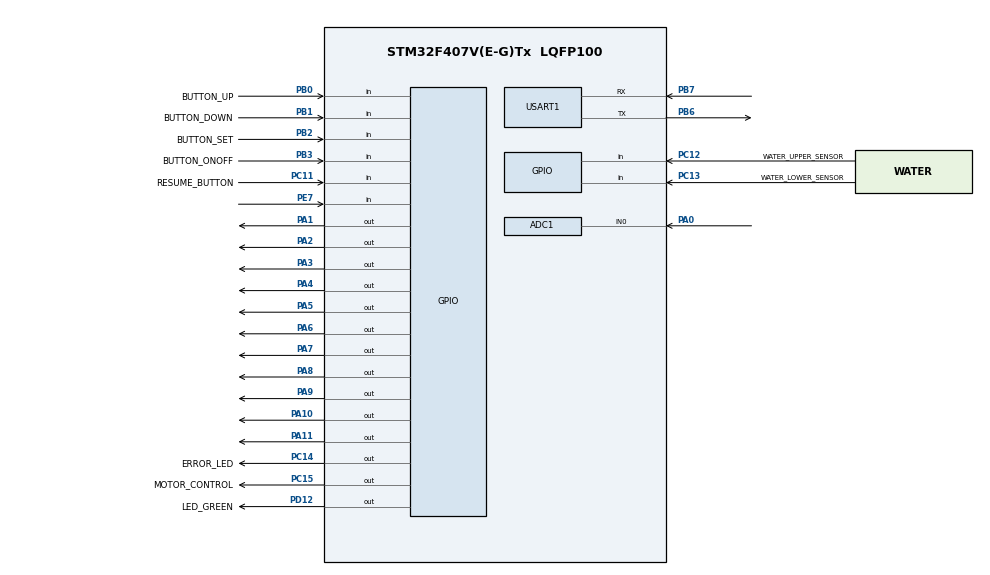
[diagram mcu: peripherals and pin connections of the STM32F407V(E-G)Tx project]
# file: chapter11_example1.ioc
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ADC1.Channel-0\#ChannelRegularConversion=ADC_CHANNEL_0
ADC1.NbrOfConversionFlag=1
ADC1.Rank-0\#ChannelRegularConversion=1
ADC1.SamplingTime-0\#ChannelRegularConversion=ADC_SAMPLETIME_15CYCLES
ADC1.master=1
Mcu.Family=STM32F4
Mcu.Name=STM32F407V(E-G)Tx
Mcu.Package=LQFP100
NVIC.PriorityGroup=NVIC_PRIORITYGROUP_4
PA0-WKUP.Signal=SharedAnalog_PA0
PA1.Signal=GPIO_Output
PA10.Signal=GPIO_Output
PA11.Signal=GPIO_Output
PA2.Signal=GPIO_Output
PA3.Signal=GPIO_Output
PA4.Signal=GPIO_Output
PA5.Signal=GPIO_Output
PA6.Signal=GPIO_Output
PA7.Signal=GPIO_Output
PA8.Signal=GPIO_Output
PA9.Signal=GPIO_Output
PB0.GPIO_Label=BUTTON_UP
PB0.GPIO_PuPd=GPIO_PULLUP
PB0.Signal=GPIO_Input
PB1.GPIO_Label=BUTTON_DOWN
PB1.GPIO_PuPd=GPIO_PULLUP
PB1.Signal=GPIO_Input
PB2.GPIO_Label=BUTTON_SET
PB2.GPIO_PuPd=GPIO_PULLUP
PB2.Signal=GPIO_Input
PB3.GPIO_Label=BUTTON_ONOFF
PB3.GPIO_PuPd=GPIO_PULLUP
PB3.Signal=GPIO_Input
PB6.Mode=Asynchronous
PB6.Signal=USART1_TX
PB7.Mode=Asynchronous
PB7.Signal=USART1_RX
PC11.GPIO_Label=RESUME_BUTTON
PC11.GPIO_PuPd=GPIO_PULLUP
PC11.Signal=GPIO_Input
PC12.GPIO_Label=WATER_UPPER_SENSOR
PC12.GPIO_PuPd=GPIO_PULLUP
PC12.Signal=GPIO_Input
PC13-ANTI_TAMP.GPIO_Label=WATER_LOWER_SENSOR
PC13-ANTI_TAMP.GPIO_PuPd=GPIO_PULLUP
PC13-ANTI_TAMP.Signal=GPIO_Input
PC14-OSC32_IN.GPIO_Label=ERROR_LED
PC14-OSC32_IN.Signal=GPIO_Output
PC15-OSC32_OUT.GPIO_Label=MOTOR_CONTROL
PC15-OSC32_OUT.Signal=GPIO_Output
PD12.GPIO_Label=LED_GREEN
PD12.Signal=GPIO_Output
PE7.Signal=GPIO_Input
ProjectManager.HeapSize=0x200
ProjectManager.StackSize=0x400
ProjectManager.TargetToolchain=STM32CubeIDE
RCC.AHBFreq_Value=16000000
RCC.APB1Freq_Value=16000000
RCC.APB2Freq_Value=16000000
RCC.CortexFreq_Value=16000000
RCC.HSE_VALUE=25000000
RCC.HSI_VALUE=16000000
RCC.LSE_VALUE=32768
RCC.SYSCLKFreq_VALUE=16000000
RCC.VCOOutputFreq_Value=192000000
SH.SharedAnalog_PA0.0=GPIO_Analog
SH.SharedAnalog_PA0.1=ADC1_IN0,IN0
USART1.VirtualMode=VM_ASYNC
board=custom

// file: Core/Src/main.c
/* USER CODE BEGIN Header */
/**
  ******************************************************************************
  * @file           : main.c
  * @brief          : Main program body
  ******************************************************************************
  * @attention
  *
  * Copyright (c) 2025 STMicroelectronics.
  * All rights reserved.
  *
  * This software is licensed under terms that can be found in the LICENSE file
  * in the root directory of this software component.
  * If no LICENSE file comes with this software, it is provided AS-IS.
  *
  ******************************************************************************
  */
/* USER CODE END Header */
#include "main.h"

/* USER CODE BEGIN Includes */
#include "app_main.h"
/* USER CODE END Includes */

void SystemClock_Config(void);
static void MX_GPIO_Init(void);
static void MX_USART1_UART_Init(void);
static void MX_ADC1_Init(void);

int main(void)
{

  /* MCU Configuration--------------------------------------------------------*/

  /* Reset of all peripherals, Initializes the Flash interface and the Systick. */
  LL_APB2_GRP1_EnableClock(LL_APB2_GRP1_PERIPH_SYSCFG);
  LL_APB1_GRP1_EnableClock(LL_APB1_GRP1_PERIPH_PWR);

  /* System interrupt init*/
  NVIC_SetPriorityGrouping(NVIC_PRIORITYGROUP_4);

  /* SysTick_IRQn interrupt configuration */
  NVIC_SetPriority(SysTick_IRQn, NVIC_EncodePriority(NVIC_GetPriorityGrouping(),15, 0));

  /* Configure the system clock */
  SystemClock_Config();

  /* Initialize all configured peripherals */
  MX_GPIO_Init();
  MX_USART1_UART_Init();
  MX_ADC1_Init();

  /* Infinite loop */
  /* USER CODE BEGIN WHILE */
app_main();
  while (1)
  {
    /* USER CODE END WHILE */

  }
}

void SystemClock_Config(void)
{
  LL_FLASH_SetLatency(LL_FLASH_LATENCY_0);
  while(LL_FLASH_GetLatency()!= LL_FLASH_LATENCY_0)
  {
  }
  LL_PWR_SetRegulVoltageScaling(LL_PWR_REGU_VOLTAGE_SCALE1);
  LL_RCC_HSI_SetCalibTrimming(16);
  LL_RCC_HSI_Enable();

   /* Wait till HSI is ready */
  while(LL_RCC_HSI_IsReady() != 1)
  {

  }
  LL_RCC_SetAHBPrescaler(LL_RCC_SYSCLK_DIV_1);
  LL_RCC_SetAPB1Prescaler(LL_RCC_APB1_DIV_1);
  LL_RCC_SetAPB2Prescaler(LL_RCC_APB2_DIV_1);
  LL_RCC_SetSysClkSource(LL_RCC_SYS_CLKSOURCE_HSI);

   /* Wait till System clock is ready */
  while(LL_RCC_GetSysClkSource() != LL_RCC_SYS_CLKSOURCE_STATUS_HSI)
  {

  }
  LL_Init1msTick(16000000);
  LL_SetSystemCoreClock(16000000);
}

static void MX_ADC1_Init(void)
{

  LL_ADC_InitTypeDef ADC_InitStruct = {0};
  LL_ADC_REG_InitTypeDef ADC_REG_InitStruct = {0};
  LL_ADC_CommonInitTypeDef ADC_CommonInitStruct = {0};

  LL_GPIO_InitTypeDef GPIO_InitStruct = {0};

  /* Peripheral clock enable */
  LL_APB2_GRP1_EnableClock(LL_APB2_GRP1_PERIPH_ADC1);

  LL_AHB1_GRP1_EnableClock(LL_AHB1_GRP1_PERIPH_GPIOA);
  /**ADC1 GPIO Configuration
  PA0-WKUP   ------> ADC1_IN0
  */
  GPIO_InitStruct.Pin = LL_GPIO_PIN_0;
  GPIO_InitStruct.Mode = LL_GPIO_MODE_ANALOG;
  GPIO_InitStruct.Pull = LL_GPIO_PULL_NO;
  LL_GPIO_Init(GPIOA, &GPIO_InitStruct);

  /* USER CODE BEGIN ADC1_Init 1 */
  /* Kích hoạt ADC */
   LL_ADC_Enable(ADC1);
   while (!LL_ADC_IsEnabled(ADC1));

   /* Hiệu chuẩn ADC (tùy chọn, nhưng nên có) */

  /* USER CODE END ADC1_Init 1 */

  /** Common config
  */
  ADC_InitStruct.Resolution = LL_ADC_RESOLUTION_12B;
  ADC_InitStruct.DataAlignment = LL_ADC_DATA_ALIGN_RIGHT;
  ADC_InitStruct.SequencersScanMode = LL_ADC_SEQ_SCAN_DISABLE;
  LL_ADC_Init(ADC1, &ADC_InitStruct);
  ADC_REG_InitStruct.TriggerSource = LL_ADC_REG_TRIG_SOFTWARE;
  ADC_REG_InitStruct.SequencerLength = LL_ADC_REG_SEQ_SCAN_DISABLE;
  ADC_REG_InitStruct.SequencerDiscont = LL_ADC_REG_SEQ_DISCONT_DISABLE;
  ADC_REG_InitStruct.ContinuousMode = LL_ADC_REG_CONV_SINGLE;
  ADC_REG_InitStruct.DMATransfer = LL_ADC_REG_DMA_TRANSFER_NONE;
  LL_ADC_REG_Init(ADC1, &ADC_REG_InitStruct);
  LL_ADC_REG_SetFlagEndOfConversion(ADC1, LL_ADC_REG_FLAG_EOC_UNITARY_CONV);
  ADC_CommonInitStruct.CommonClock = LL_ADC_CLOCK_SYNC_PCLK_DIV2;
  ADC_CommonInitStruct.Multimode = LL_ADC_MULTI_INDEPENDENT;
  LL_ADC_CommonInit(__LL_ADC_COMMON_INSTANCE(ADC1), &ADC_CommonInitStruct);

  /** Configure Regular Channel
  */
  LL_ADC_REG_SetSequencerRanks(ADC1, LL_ADC_REG_RANK_1, LL_ADC_CHANNEL_0);
  LL_ADC_SetChannelSamplingTime(ADC1, LL_ADC_CHANNEL_0, LL_ADC_SAMPLINGTIME_15CYCLES);

}

static void MX_USART1_UART_Init(void)
{

  LL_USART_InitTypeDef USART_InitStruct = {0};

  LL_GPIO_InitTypeDef GPIO_InitStruct = {0};

  /* Peripheral clock enable */
  LL_APB2_GRP1_EnableClock(LL_APB2_GRP1_PERIPH_USART1);

  LL_AHB1_GRP1_EnableClock(LL_AHB1_GRP1_PERIPH_GPIOB);
  /**USART1 GPIO Configuration
  PB6   ------> USART1_TX
  PB7   ------> USART1_RX
  */
  GPIO_InitStruct.Pin = LL_GPIO_PIN_6|LL_GPIO_PIN_7;
  GPIO_InitStruct.Mode = LL_GPIO_MODE_ALTERNATE;
  GPIO_InitStruct.Speed = LL_GPIO_SPEED_FREQ_VERY_HIGH;
  GPIO_InitStruct.OutputType = LL_GPIO_OUTPUT_PUSHPULL;
  GPIO_InitStruct.Pull = LL_GPIO_PULL_NO;
  GPIO_InitStruct.Alternate = LL_GPIO_AF_7;
  LL_GPIO_Init(GPIOB, &GPIO_InitStruct);

  USART_InitStruct.BaudRate = 115200;
  USART_InitStruct.DataWidth = LL_USART_DATAWIDTH_8B;
  USART_InitStruct.StopBits = LL_USART_STOPBITS_1;
  USART_InitStruct.Parity = LL_USART_PARITY_NONE;
  USART_InitStruct.TransferDirection = LL_USART_DIRECTION_TX_RX;
  USART_InitStruct.HardwareFlowControl = LL_USART_HWCONTROL_NONE;
  USART_InitStruct.OverSampling = LL_USART_OVERSAMPLING_16;
  LL_USART_Init(USART1, &USART_InitStruct);
  LL_USART_ConfigAsyncMode(USART1);
  LL_USART_Enable(USART1);

}

static void MX_GPIO_Init(void)
{
  LL_GPIO_InitTypeDef GPIO_InitStruct = {0};

  /* GPIO Ports Clock Enable */
  LL_AHB1_GRP1_EnableClock(LL_AHB1_GRP1_PERIPH_GPIOC);
  LL_AHB1_GRP1_EnableClock(LL_AHB1_GRP1_PERIPH_GPIOA);
  LL_AHB1_GRP1_EnableClock(LL_AHB1_GRP1_PERIPH_GPIOB);
  LL_AHB1_GRP1_EnableClock(LL_AHB1_GRP1_PERIPH_GPIOE);
  LL_AHB1_GRP1_EnableClock(LL_AHB1_GRP1_PERIPH_GPIOD);

  /**/
  LL_GPIO_ResetOutputPin(GPIOC, ERROR_LED_Pin|MOTOR_CONTROL_Pin);

  /**/
  LL_GPIO_ResetOutputPin(GPIOA, LL_GPIO_PIN_1|LL_GPIO_PIN_2|LL_GPIO_PIN_3|LL_GPIO_PIN_4
                          |LL_GPIO_PIN_5|LL_GPIO_PIN_6|LL_GPIO_PIN_7|LL_GPIO_PIN_8
                          |LL_GPIO_PIN_9|LL_GPIO_PIN_10|LL_GPIO_PIN_11);

  /**/
  LL_GPIO_ResetOutputPin(LED_GREEN_GPIO_Port, LED_GREEN_Pin);

  /**/
  GPIO_InitStruct.Pin = WATER_LOWER_SENSOR_Pin|RESUME_BUTTON_Pin|WATER_UPPER_SENSOR_Pin;
  GPIO_InitStruct.Mode = LL_GPIO_MODE_INPUT;
  GPIO_InitStruct.Pull = LL_GPIO_PULL_UP;
  LL_GPIO_Init(GPIOC, &GPIO_InitStruct);

  /**/
  GPIO_InitStruct.Pin = ERROR_LED_Pin|MOTOR_CONTROL_Pin;
  GPIO_InitStruct.Mode = LL_GPIO_MODE_OUTPUT;
  GPIO_InitStruct.Speed = LL_GPIO_SPEED_FREQ_LOW;
  GPIO_InitStruct.OutputType = LL_GPIO_OUTPUT_PUSHPULL;
  GPIO_InitStruct.Pull = LL_GPIO_PULL_NO;
  LL_GPIO_Init(GPIOC, &GPIO_InitStruct);

  /**/
  GPIO_InitStruct.Pin = LL_GPIO_PIN_1|LL_GPIO_PIN_2|LL_GPIO_PIN_3|LL_GPIO_PIN_4
                          |LL_GPIO_PIN_5|LL_GPIO_PIN_6|LL_GPIO_PIN_7|LL_GPIO_PIN_8
                          |LL_GPIO_PIN_9|LL_GPIO_PIN_10|LL_GPIO_PIN_11;
  GPIO_InitStruct.Mode = LL_GPIO_MODE_OUTPUT;
  GPIO_InitStruct.Speed = LL_GPIO_SPEED_FREQ_LOW;
  GPIO_InitStruct.OutputType = LL_GPIO_OUTPUT_PUSHPULL;
  GPIO_InitStruct.Pull = LL_GPIO_PULL_NO;
  LL_GPIO_Init(GPIOA, &GPIO_InitStruct);

  /**/
  GPIO_InitStruct.Pin = BUTTON_UP_Pin|BUTTON_DOWN_Pin|BUTTON_SET_Pin|BUTTON_ONOFF_Pin;
  GPIO_InitStruct.Mode = LL_GPIO_MODE_INPUT;
  GPIO_InitStruct.Pull = LL_GPIO_PULL_UP;
  LL_GPIO_Init(GPIOB, &GPIO_InitStruct);

  /**/
  GPIO_InitStruct.Pin = LL_GPIO_PIN_7;
  GPIO_InitStruct.Mode = LL_GPIO_MODE_INPUT;
  GPIO_InitStruct.Pull = LL_GPIO_PULL_NO;
  LL_GPIO_Init(GPIOE, &GPIO_InitStruct);

  /**/
  GPIO_InitStruct.Pin = LED_GREEN_Pin;
  GPIO_InitStruct.Mode = LL_GPIO_MODE_OUTPUT;
  GPIO_InitStruct.Speed = LL_GPIO_SPEED_FREQ_LOW;
  GPIO_InitStruct.OutputType = LL_GPIO_OUTPUT_PUSHPULL;
  GPIO_InitStruct.Pull = LL_GPIO_PULL_NO;
  LL_GPIO_Init(LED_GREEN_GPIO_Port, &GPIO_InitStruct);

}

void Error_Handler(void)
{
  __disable_irq();
  while (1)
  {
  }
}
